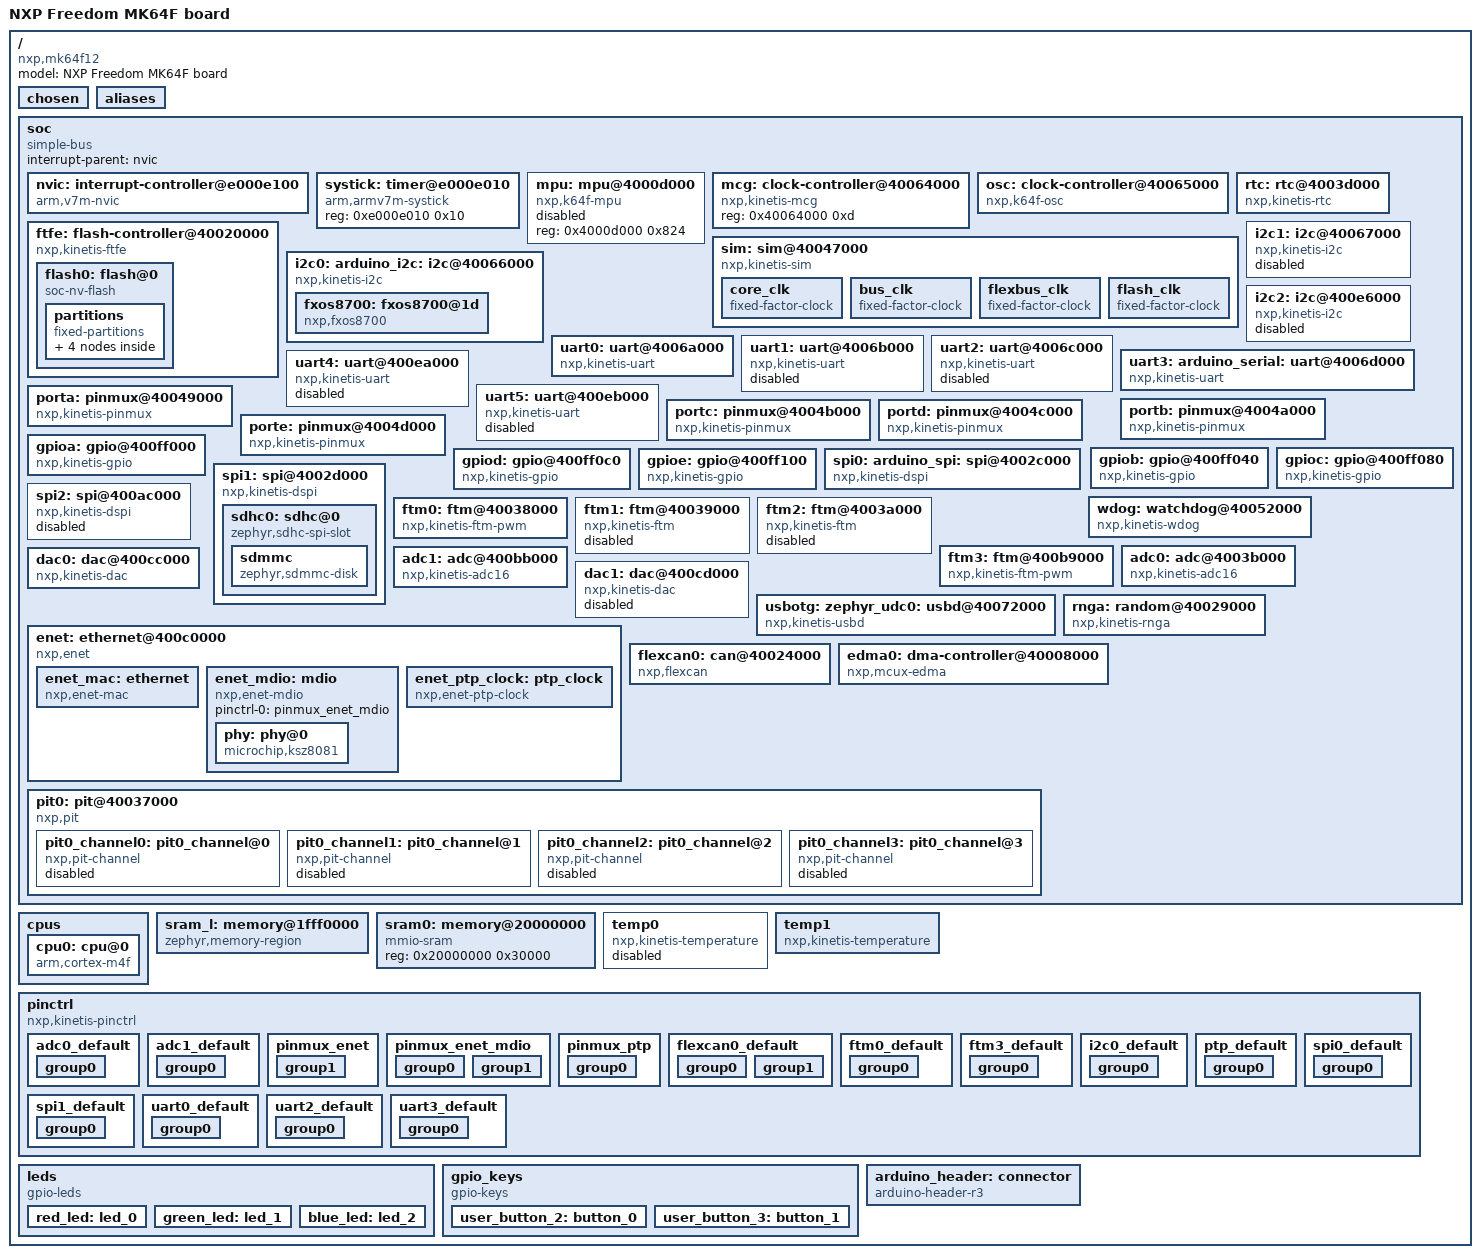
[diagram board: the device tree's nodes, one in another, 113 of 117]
/dts-v1/;

/ {
	#address-cells = < 0x1 >;
	#size-cells = < 0x1 >;
	model = "NXP Freedom MK64F board";
	compatible = "nxp,mk64f12", "nxp,k64f", "nxp,k6x";
	chosen {
		zephyr,entropy = &rnga;
		zephyr,flash-controller = &ftfe;
		zephyr,sram = &sram0;
		zephyr,flash = &flash0;
		zephyr,code-partition = &slot0_partition;
		zephyr,console = &uart0;
		zephyr,shell-uart = &uart0;
		zephyr,uart-pipe = &uart0;
		zephyr,canbus = &flexcan0;
		zephyr,uart-mcumgr = &uart0;
	};
	aliases {
		watchdog0 = &wdog;
		led0 = &green_led;
		led1 = &blue_led;
		led2 = &red_led;
		sw0 = &user_button_3;
		sw1 = &user_button_2;
		magn0 = &fxos8700;
		accel0 = &fxos8700;
	};
	soc {
		#address-cells = < 0x1 >;
		#size-cells = < 0x1 >;
		compatible = "simple-bus";
		interrupt-parent = < &nvic >;
		ranges;
		nvic: interrupt-controller@e000e100 {
			#address-cells = < 0x1 >;
			compatible = "arm,v7m-nvic";
			reg = < 0xe000e100 0xc00 >;
			interrupt-controller;
			#interrupt-cells = < 0x2 >;
			arm,num-irq-priority-bits = < 0x4 >;
			phandle = < 0x1 >;
		};
		systick: timer@e000e010 {
			compatible = "arm,armv7m-systick";
			reg = < 0xe000e010 0x10 >;
		};
		mpu: mpu@4000d000 {
			compatible = "nxp,k64f-mpu";
			reg = < 0x4000d000 0x824 >;
			status = "disabled";
		};
		mcg: clock-controller@40064000 {
			compatible = "nxp,kinetis-mcg";
			reg = < 0x40064000 0xd >;
			#clock-cells = < 0x1 >;
			phandle = < 0x2 >;
		};
		osc: clock-controller@40065000 {
			compatible = "nxp,k64f-osc";
			reg = < 0x40065000 0x4 >;
			enable-external-reference;
		};
		rtc: rtc@4003d000 {
			compatible = "nxp,kinetis-rtc";
			reg = < 0x4003d000 0x1000 >;
			interrupts = < 0x2e 0x0 >, < 0x2f 0x0 >;
			interrupt-names = "alarm", "seconds";
			clock-frequency = < 0x8000 >;
			prescaler = < 0x8000 >;
		};
		sim: sim@40047000 {
			compatible = "nxp,kinetis-sim";
			reg = < 0x40047000 0x1060 >;
			#clock-cells = < 0x3 >;
			pllfll-select = < 0x1 >;
			er32k-select = < 0x2 >;
			phandle = < 0x3 >;
			core_clk {
				compatible = "fixed-factor-clock";
				clocks = < &mcg 0x1 >;
				clock-div = < 0x1 >;
				#clock-cells = < 0x0 >;
			};
			bus_clk {
				compatible = "fixed-factor-clock";
				clocks = < &mcg 0x1 >;
				clock-div = < 0x2 >;
				#clock-cells = < 0x0 >;
			};
			flexbus_clk {
				compatible = "fixed-factor-clock";
				clocks = < &mcg 0x1 >;
				clock-div = < 0x3 >;
				#clock-cells = < 0x0 >;
			};
			flash_clk {
				compatible = "fixed-factor-clock";
				clocks = < &mcg 0x1 >;
				clock-div = < 0x5 >;
				#clock-cells = < 0x0 >;
			};
		};
		ftfe: flash-controller@40020000 {
			compatible = "nxp,kinetis-ftfe";
			reg = < 0x40020000 0x18 >;
			interrupts = < 0x12 0x0 >, < 0x13 0x0 >;
			interrupt-names = "command-complete", "read-collision";
			status = "okay";
			#address-cells = < 0x1 >;
			#size-cells = < 0x1 >;
			flash0: flash@0 {
				compatible = "soc-nv-flash";
				reg = < 0x0 0x100000 >;
				erase-block-size = < 0x1000 >;
				write-block-size = < 0x8 >;
				partitions {
					compatible = "fixed-partitions";
					#address-cells = < 0x1 >;
					#size-cells = < 0x1 >;
					boot_partition: partition@0 {
						label = "mcuboot";
						reg = < 0x0 0x10000 >;
						read-only;
					};
					slot0_partition: partition@10000 {
						label = "image-0";
						reg = < 0x10000 0x6a000 >;
					};
					slot1_partition: partition@7a000 {
						label = "image-1";
						reg = < 0x7a000 0x68000 >;
					};
					storage_partition: partition@e2000 {
						label = "storage";
						reg = < 0xe2000 0x1e000 >;
					};
				};
			};
		};
		i2c0: arduino_i2c: i2c@40066000 {
			compatible = "nxp,kinetis-i2c";
			clock-frequency = < 0x186a0 >;
			#address-cells = < 0x1 >;
			#size-cells = < 0x0 >;
			reg = < 0x40066000 0x1000 >;
			interrupts = < 0x18 0x0 >;
			clocks = < &sim 0x2 0x1034 0x6 >;
			status = "okay";
			pinctrl-0 = < &i2c0_default >;
			pinctrl-names = "default";
			fxos8700: fxos8700@1d {
				compatible = "nxp,fxos8700";
				reg = < 0x1d >;
				int1-gpios = < &gpioc 0x6 0x1 >;
				int2-gpios = < &gpioc 0xd 0x1 >;
			};
		};
		i2c1: i2c@40067000 {
			compatible = "nxp,kinetis-i2c";
			clock-frequency = < 0x186a0 >;
			#address-cells = < 0x1 >;
			#size-cells = < 0x0 >;
			reg = < 0x40067000 0x1000 >;
			interrupts = < 0x19 0x0 >;
			clocks = < &sim 0x2 0x1034 0x7 >;
			status = "disabled";
		};
		i2c2: i2c@400e6000 {
			compatible = "nxp,kinetis-i2c";
			clock-frequency = < 0x186a0 >;
			#address-cells = < 0x1 >;
			#size-cells = < 0x0 >;
			reg = < 0x400e6000 0x1000 >;
			interrupts = < 0x4a 0x0 >;
			clocks = < &sim 0x2 0x1028 0x6 >;
			status = "disabled";
		};
		uart0: uart@4006a000 {
			compatible = "nxp,kinetis-uart";
			reg = < 0x4006a000 0x1000 >;
			interrupts = < 0x1f 0x0 >, < 0x20 0x0 >;
			interrupt-names = "status", "error";
			clocks = < &sim 0x0 0x1034 0xa >;
			status = "okay";
			current-speed = < 0x1c200 >;
			pinctrl-0 = < &uart0_default >;
			pinctrl-names = "default";
		};
		uart1: uart@4006b000 {
			compatible = "nxp,kinetis-uart";
			reg = < 0x4006b000 0x1000 >;
			interrupts = < 0x21 0x0 >, < 0x22 0x0 >;
			interrupt-names = "status", "error";
			clocks = < &sim 0x0 0x1034 0xb >;
			status = "disabled";
		};
		uart2: uart@4006c000 {
			compatible = "nxp,kinetis-uart";
			reg = < 0x4006c000 0x1000 >;
			interrupts = < 0x23 0x0 >, < 0x24 0x0 >;
			interrupt-names = "status", "error";
			clocks = < &sim 0x2 0x1034 0xc >;
			status = "disabled";
			pinctrl-0 = < &uart2_default >;
			pinctrl-names = "default";
		};
		uart3: arduino_serial: uart@4006d000 {
			compatible = "nxp,kinetis-uart";
			reg = < 0x4006d000 0x1000 >;
			interrupts = < 0x25 0x0 >, < 0x26 0x0 >;
			interrupt-names = "status", "error";
			clocks = < &sim 0x2 0x1034 0xd >;
			status = "okay";
			current-speed = < 0x1c200 >;
			pinctrl-0 = < &uart3_default >;
			pinctrl-names = "default";
		};
		uart4: uart@400ea000 {
			compatible = "nxp,kinetis-uart";
			reg = < 0x400ea000 0x1000 >;
			interrupts = < 0x42 0x0 >, < 0x43 0x0 >;
			interrupt-names = "status", "error";
			clocks = < &sim 0x2 0x1028 0xa >;
			status = "disabled";
		};
		uart5: uart@400eb000 {
			compatible = "nxp,kinetis-uart";
			reg = < 0x400eb000 0x1000 >;
			interrupts = < 0x44 0x0 >, < 0x45 0x0 >;
			interrupt-names = "status", "error";
			clocks = < &sim 0x2 0x1028 0xb >;
			status = "disabled";
		};
		porta: pinmux@40049000 {
			compatible = "nxp,kinetis-pinmux";
			reg = < 0x40049000 0xd0 >;
			clocks = < &sim 0x2 0x1038 0x9 >;
			phandle = < 0x9 >;
		};
		portb: pinmux@4004a000 {
			compatible = "nxp,kinetis-pinmux";
			reg = < 0x4004a000 0xd0 >;
			clocks = < &sim 0x2 0x1038 0xa >;
			phandle = < 0xa >;
		};
		portc: pinmux@4004b000 {
			compatible = "nxp,kinetis-pinmux";
			reg = < 0x4004b000 0xd0 >;
			clocks = < &sim 0x2 0x1038 0xb >;
			phandle = < 0xb >;
		};
		portd: pinmux@4004c000 {
			compatible = "nxp,kinetis-pinmux";
			reg = < 0x4004c000 0xd0 >;
			clocks = < &sim 0x2 0x1038 0xc >;
			phandle = < 0xc >;
		};
		porte: pinmux@4004d000 {
			compatible = "nxp,kinetis-pinmux";
			reg = < 0x4004d000 0xd0 >;
			clocks = < &sim 0x2 0x1038 0xd >;
			phandle = < 0xd >;
		};
		gpioa: gpio@400ff000 {
			compatible = "nxp,kinetis-gpio";
			status = "okay";
			reg = < 0x400ff000 0x40 >;
			interrupts = < 0x3b 0x2 >;
			gpio-controller;
			#gpio-cells = < 0x2 >;
			nxp,kinetis-port = < &porta >;
			phandle = < 0x20 >;
		};
		gpiob: gpio@400ff040 {
			compatible = "nxp,kinetis-gpio";
			status = "okay";
			reg = < 0x400ff040 0x40 >;
			interrupts = < 0x3c 0x2 >;
			gpio-controller;
			#gpio-cells = < 0x2 >;
			nxp,kinetis-port = < &portb >;
			phandle = < 0x1f >;
		};
		gpioc: gpio@400ff080 {
			compatible = "nxp,kinetis-gpio";
			status = "okay";
			reg = < 0x400ff080 0x40 >;
			interrupts = < 0x3d 0x2 >;
			gpio-controller;
			#gpio-cells = < 0x2 >;
			nxp,kinetis-port = < &portc >;
			phandle = < 0x5 >;
		};
		gpiod: gpio@400ff0c0 {
			compatible = "nxp,kinetis-gpio";
			status = "okay";
			reg = < 0x400ff0c0 0x40 >;
			interrupts = < 0x3e 0x2 >;
			gpio-controller;
			#gpio-cells = < 0x2 >;
			nxp,kinetis-port = < &portd >;
			phandle = < 0x21 >;
		};
		gpioe: gpio@400ff100 {
			compatible = "nxp,kinetis-gpio";
			status = "okay";
			reg = < 0x400ff100 0x40 >;
			interrupts = < 0x3f 0x2 >;
			gpio-controller;
			#gpio-cells = < 0x2 >;
			nxp,kinetis-port = < &porte >;
			phandle = < 0x11 >;
		};
		spi0: arduino_spi: spi@4002c000 {
			compatible = "nxp,kinetis-dspi";
			reg = < 0x4002c000 0x88 >;
			interrupts = < 0x1a 0x3 >;
			dmas = < &edma0 0x0 0xe >, < &edma0 0x0 0xf >;
			dma-names = "rx", "tx";
			rx-fifo-size = < 0x4 >;
			tx-fifo-size = < 0x4 >;
			clocks = < &sim 0x2 0x103c 0xc >;
			#address-cells = < 0x1 >;
			#size-cells = < 0x0 >;
			status = "okay";
			pinctrl-0 = < &spi0_default >;
			pinctrl-names = "default";
		};
		spi1: spi@4002d000 {
			compatible = "nxp,kinetis-dspi";
			reg = < 0x4002d000 0x88 >;
			interrupts = < 0x1b 0x3 >;
			dmas = < &edma0 0x0 0x10 >, < &edma0 0x0 0x10 >;
			dma-names = "rx", "tx";
			rx-fifo-size = < 0x1 >;
			tx-fifo-size = < 0x1 >;
			nxp,rx-tx-chn-share;
			clocks = < &sim 0x2 0x103c 0xd >;
			#address-cells = < 0x1 >;
			#size-cells = < 0x0 >;
			status = "okay";
			pinctrl-0 = < &spi1_default >;
			pinctrl-names = "default";
			cs-gpios = < &gpioe 0x4 0x1 >;
			sdhc0: sdhc@0 {
				compatible = "zephyr,sdhc-spi-slot";
				reg = < 0x0 >;
				status = "okay";
				spi-max-frequency = < 0x16e3600 >;
				sdmmc {
					compatible = "zephyr,sdmmc-disk";
					status = "okay";
				};
			};
		};
		spi2: spi@400ac000 {
			compatible = "nxp,kinetis-dspi";
			reg = < 0x400ac000 0x88 >;
			interrupts = < 0x41 0x3 >;
			dmas = < &edma0 0x0 0x26 >, < &edma0 0x0 0x27 >;
			dma-names = "rx", "tx";
			rx-fifo-size = < 0x1 >;
			tx-fifo-size = < 0x1 >;
			nxp,rx-tx-chn-share;
			clocks = < &sim 0x2 0x1030 0xc >;
			#address-cells = < 0x1 >;
			#size-cells = < 0x0 >;
			status = "disabled";
		};
		wdog: watchdog@40052000 {
			compatible = "nxp,kinetis-wdog";
			reg = < 0x40052000 0x10 >;
			interrupts = < 0x16 0x0 >;
			clocks = < &sim 0x13 0x0 0x0 >;
		};
		ftm0: ftm@40038000 {
			compatible = "nxp,kinetis-ftm-pwm";
			reg = < 0x40038000 0x98 >;
			interrupts = < 0x2a 0x0 >;
			clocks = < &mcg 0x0 >;
			prescaler = < 0x10 >;
			status = "okay";
			#pwm-cells = < 0x3 >;
			pinctrl-0 = < &ftm0_default >;
			pinctrl-names = "default";
			clock-source = "fixed";
		};
		ftm1: ftm@40039000 {
			compatible = "nxp,kinetis-ftm";
			reg = < 0x40039000 0x98 >;
			interrupts = < 0x2b 0x0 >;
			clocks = < &mcg 0x0 >;
			prescaler = < 0x10 >;
			status = "disabled";
		};
		ftm2: ftm@4003a000 {
			compatible = "nxp,kinetis-ftm";
			reg = < 0x4003a000 0x98 >;
			interrupts = < 0x2c 0x0 >;
			clocks = < &mcg 0x0 >;
			prescaler = < 0x10 >;
			status = "disabled";
		};
		ftm3: ftm@400b9000 {
			compatible = "nxp,kinetis-ftm-pwm";
			reg = < 0x400b9000 0x98 >;
			interrupts = < 0x47 0x0 >;
			clocks = < &mcg 0x0 >;
			prescaler = < 0x10 >;
			status = "okay";
			#pwm-cells = < 0x3 >;
			pinctrl-0 = < &ftm3_default >;
			pinctrl-names = "default";
			clock-source = "fixed";
		};
		adc0: adc@4003b000 {
			compatible = "nxp,kinetis-adc16";
			reg = < 0x4003b000 0x70 >;
			clocks = < &sim 0x7 0x0 0xf >, < &sim 0x7 0x7 0x80 >;
			dmas = < &edma0 0x0 0x28 >;
			dma-names = "adc0";
			clk-source = < 0x0 >;
			interrupts = < 0x27 0x0 >;
			status = "okay";
			#io-channel-cells = < 0x1 >;
			pinctrl-0 = < &adc0_default >;
			pinctrl-names = "default";
			phandle = < 0x1d >;
		};
		adc1: adc@400bb000 {
			compatible = "nxp,kinetis-adc16";
			reg = < 0x400bb000 0x70 >;
			clocks = < &sim 0x7 0x8 0xf00 >, < &sim 0x7 0xf 0x8000 >;
			dmas = < &edma0 0x0 0x29 >;
			dma-names = "adc1";
			clk-source = < 0x0 >;
			interrupts = < 0x49 0x0 >;
			status = "okay";
			#io-channel-cells = < 0x1 >;
			pinctrl-0 = < &adc1_default >;
			pinctrl-names = "default";
			phandle = < 0x1e >;
		};
		dac0: dac@400cc000 {
			compatible = "nxp,kinetis-dac";
			reg = < 0x400cc000 0x1000 >;
			interrupts = < 0x38 0x0 >;
			voltage-reference = < 0x2 >;
			status = "okay";
			#io-channel-cells = < 0x1 >;
		};
		dac1: dac@400cd000 {
			compatible = "nxp,kinetis-dac";
			reg = < 0x400cd000 0x1000 >;
			interrupts = < 0x48 0x0 >;
			voltage-reference = < 0x1 >;
			status = "disabled";
			#io-channel-cells = < 0x1 >;
		};
		usbotg: zephyr_udc0: usbd@40072000 {
			compatible = "nxp,kinetis-usbd";
			reg = < 0x40072000 0x1000 >;
			interrupts = < 0x35 0x1 >;
			interrupt-names = "usb_otg";
			num-bidir-endpoints = < 0x8 >;
			status = "okay";
		};
		enet: ethernet@400c0000 {
			compatible = "nxp,enet";
			reg = < 0x400c0000 0x620 >;
			clocks = < &sim 0x10e1 0x0 0x0 >;
			enet_mac: ethernet {
				compatible = "nxp,enet-mac";
				interrupts = < 0x53 0x0 >, < 0x54 0x0 >, < 0x55 0x0 >;
				interrupt-names = "TX", "RX", "ERR";
				nxp,mdio = < &enet_mdio >;
				nxp,ptp-clock = < &enet_ptp_clock >;
				phy-connection-type = "rmii";
				status = "okay";
				pinctrl-0 = < &pinmux_enet >;
				pinctrl-names = "default";
				phy-handle = < &phy >;
				zephyr,random-mac-address;
			};
			enet_mdio: mdio {
				compatible = "nxp,enet-mdio";
				status = "okay";
				#address-cells = < 0x1 >;
				#size-cells = < 0x0 >;
				pinctrl-0 = < &pinmux_enet_mdio >;
				pinctrl-names = "default";
				phandle = < 0x16 >;
				phy: phy@0 {
					compatible = "microchip,ksz8081";
					reg = < 0x0 >;
					status = "okay";
					microchip,interface-type = "rmii-25MHz";
					phandle = < 0x19 >;
				};
			};
			enet_ptp_clock: ptp_clock {
				compatible = "nxp,enet-ptp-clock";
				interrupts = < 0x52 0x0 >;
				interrupt-names = "IEEE1588_TMR";
				clocks = < &sim 0x10e2 0x0 0x0 >;
				status = "okay";
				pinctrl-0 = < &pinmux_ptp >;
				pinctrl-names = "default";
				phandle = < 0x17 >;
			};
		};
		rnga: random@40029000 {
			compatible = "nxp,kinetis-rnga";
			reg = < 0x40029000 0x1000 >;
			status = "okay";
			interrupts = < 0x17 0x0 >;
		};
		flexcan0: can@40024000 {
			compatible = "nxp,flexcan";
			reg = < 0x40024000 0x1000 >;
			interrupts = < 0x4b 0x0 >, < 0x4c 0x0 >, < 0x4d 0x0 >, < 0x4e 0x0 >, < 0x4f 0x0 >, < 0x50 0x0 >;
			interrupt-names = "mb-0-15", "bus-off", "error", "tx-warning", "rx-warning", "wake-up";
			clocks = < &sim 0x2 0x103c 0x4 >;
			clk-source = < 0x1 >;
			status = "okay";
			pinctrl-0 = < &flexcan0_default >;
			pinctrl-names = "default";
		};
		edma0: dma-controller@40008000 {
			#dma-cells = < 0x2 >;
			compatible = "nxp,mcux-edma";
			dma-channels = < 0x10 >;
			dma-requests = < 0x40 >;
			nxp,mem2mem;
			reg = < 0x40008000 0x1000 >, < 0x40021000 0x1000 >;
			interrupts = < 0x0 0x0 >, < 0x1 0x0 >, < 0x2 0x0 >, < 0x3 0x0 >, < 0x4 0x0 >, < 0x5 0x0 >, < 0x6 0x0 >, < 0x7 0x0 >, < 0x8 0x0 >, < 0x9 0x0 >, < 0xa 0x0 >, < 0xb 0x0 >, < 0xc 0x0 >, < 0xd 0x0 >, < 0xe 0x0 >, < 0xf 0x0 >, < 0x10 0x0 >;
			clocks = < &sim 0x0 0x1040 0x2 >, < &sim 0x2 0x103c 0x2 >;
			status = "okay";
			phandle = < 0xe >;
		};
		pit0: pit@40037000 {
			compatible = "nxp,pit";
			reg = < 0x40037000 0x1000 >;
			clocks = < &sim 0x2 0x103c 0x17 >;
			status = "okay";
			max-load-value = < 0xffffffff >;
			#address-cells = < 0x1 >;
			#size-cells = < 0x0 >;
			pit0_channel0: pit0_channel@0 {
				compatible = "nxp,pit-channel";
				reg = < 0x0 >;
				interrupts = < 0x30 0x0 >;
				status = "disabled";
			};
			pit0_channel1: pit0_channel@1 {
				compatible = "nxp,pit-channel";
				reg = < 0x1 >;
				interrupts = < 0x31 0x0 >;
				status = "disabled";
			};
			pit0_channel2: pit0_channel@2 {
				compatible = "nxp,pit-channel";
				reg = < 0x2 >;
				interrupts = < 0x32 0x0 >;
				status = "disabled";
			};
			pit0_channel3: pit0_channel@3 {
				compatible = "nxp,pit-channel";
				reg = < 0x3 >;
				interrupts = < 0x33 0x0 >;
				status = "disabled";
			};
		};
	};
	cpus {
		#address-cells = < 0x1 >;
		#size-cells = < 0x0 >;
		cpu0: cpu@0 {
			device_type = "cpu";
			compatible = "arm,cortex-m4f";
			reg = < 0x0 >;
			clock-frequency = < 0x7270e00 >;
		};
	};
	sram_l: memory@1fff0000 {
		compatible = "zephyr,memory-region", "mmio-sram";
		reg = < 0x1fff0000 0x10000 >;
		zephyr,memory-region = "SRAML";
	};
	sram0: memory@20000000 {
		compatible = "mmio-sram";
		reg = < 0x20000000 0x30000 >;
	};
	temp0: temp0 {
		compatible = "nxp,kinetis-temperature";
		io-channels = < &adc0 0x1a >, < &adc0 0x1b >;
		io-channel-names = "SENSOR", "BANDGAP";
		bandgap-voltage = < 0xf4240 >;
		vtemp25 = < 0xaece0 >;
		sensor-slope-cold = < 0x654 >;
		sensor-slope-hot = < 0x654 >;
		status = "disabled";
	};
	temp1: temp1 {
		compatible = "nxp,kinetis-temperature";
		io-channels = < &adc1 0x1a >, < &adc1 0x1b >;
		io-channel-names = "SENSOR", "BANDGAP";
		bandgap-voltage = < 0xf4240 >;
		vtemp25 = < 0xaece0 >;
		sensor-slope-cold = < 0x654 >;
		sensor-slope-hot = < 0x654 >;
		status = "okay";
	};
	pinctrl: pinctrl {
		compatible = "nxp,kinetis-pinctrl";
		status = "okay";
		adc0_default: adc0_default {
			phandle = < 0x14 >;
			group0 {
				pinmux = < 0x20000000 >;
				drive-strength = "low";
				slew-rate = "fast";
			};
		};
		adc1_default: adc1_default {
			phandle = < 0x15 >;
			group0 {
				pinmux = < 0x12800000 >;
				drive-strength = "low";
				slew-rate = "fast";
			};
		};
		pinmux_enet: pinmux_enet {
			phandle = < 0x18 >;
			group1 {
				pinmux = < 0x1400400 >, < 0x3000400 >, < 0x3400400 >, < 0x3800400 >, < 0x3c00400 >, < 0x4000400 >, < 0x4400400 >;
				drive-strength = "low";
				slew-rate = "fast";
			};
		};
		pinmux_enet_mdio: pinmux_enet_mdio {
			phandle = < 0x1a >;
			group0 {
				pinmux = < 0x10000400 >;
				drive-strength = "low";
				drive-open-drain;
				bias-pull-up;
				slew-rate = "fast";
			};
			group1 {
				pinmux = < 0x10400400 >;
				drive-strength = "low";
				slew-rate = "fast";
			};
		};
		pinmux_ptp: pinmux_ptp {
			phandle = < 0x1b >;
			group0 {
				pinmux = < 0x24000400 >, < 0x24400400 >, < 0x24800400 >;
				drive-strength = "low";
				slew-rate = "fast";
			};
		};
		flexcan0_default: flexcan0_default {
			phandle = < 0x1c >;
			group0 {
				pinmux = < 0x14c00200 >;
				drive-strength = "low";
				bias-pull-up;
				slew-rate = "fast";
			};
			group1 {
				pinmux = < 0x14800200 >;
				drive-strength = "low";
				slew-rate = "fast";
			};
		};
		ftm0_default: ftm0_default {
			phandle = < 0x12 >;
			group0 {
				pinmux = < 0x20400400 >;
				drive-strength = "low";
				slew-rate = "fast";
			};
		};
		ftm3_default: ftm3_default {
			phandle = < 0x13 >;
			group0 {
				pinmux = < 0x22000300 >, < 0x22400300 >;
				drive-strength = "low";
				slew-rate = "fast";
			};
		};
		i2c0_default: i2c0_default {
			phandle = < 0x4 >;
			group0 {
				pinmux = < 0x46000500 >, < 0x46400500 >;
				drive-strength = "low";
				drive-open-drain;
				slew-rate = "fast";
			};
		};
		ptp_default: ptp_default {
			group0 {
				pinmux = < 0x24000400 >, < 0x24400400 >, < 0x24800400 >;
				drive-strength = "low";
				slew-rate = "fast";
			};
		};
		spi0_default: spi0_default {
			phandle = < 0xf >;
			group0 {
				pinmux = < 0x30000200 >, < 0x30400200 >, < 0x30800200 >, < 0x30c00200 >;
				drive-strength = "low";
				slew-rate = "fast";
			};
		};
		spi1_default: spi1_default {
			phandle = < 0x10 >;
			group0 {
				pinmux = < 0x41000200 >, < 0x40800200 >, < 0x40c00700 >, < 0x40400700 >;
				drive-strength = "low";
				slew-rate = "fast";
			};
		};
		uart0_default: uart0_default {
			phandle = < 0x6 >;
			group0 {
				pinmux = < 0x14000300 >, < 0x14400300 >;
				drive-strength = "low";
				slew-rate = "fast";
			};
		};
		uart2_default: uart2_default {
			phandle = < 0x7 >;
			group0 {
				pinmux = < 0x30400300 >, < 0x30000300 >, < 0x30800300 >, < 0x30c00300 >;
				drive-strength = "low";
				slew-rate = "fast";
			};
		};
		uart3_default: uart3_default {
			phandle = < 0x8 >;
			group0 {
				pinmux = < 0x24000300 >, < 0x24400300 >;
				drive-strength = "low";
				slew-rate = "fast";
			};
		};
	};
	leds {
		compatible = "gpio-leds";
		red_led: led_0 {
			gpios = < &gpiob 0x16 0x1 >;
			label = "User LD1";
		};
		green_led: led_1 {
			gpios = < &gpioe 0x1a 0x1 >;
			label = "User LD2";
		};
		blue_led: led_2 {
			gpios = < &gpiob 0x15 0x1 >;
			label = "User LD3";
		};
	};
	gpio_keys {
		compatible = "gpio-keys";
		user_button_2: button_0 {
			label = "User SW2";
			gpios = < &gpioc 0x6 0x1 >;
			zephyr,code = < 0xb >;
		};
		user_button_3: button_1 {
			label = "User SW3";
			gpios = < &gpioa 0x4 0x1 >;
			zephyr,code = < 0x2 >;
		};
	};
	arduino_header: connector {
		compatible = "arduino-header-r3";
		#gpio-cells = < 0x2 >;
		gpio-map-mask = < 0xffffffff 0xffffffc0 >;
		gpio-map-pass-thru = < 0x0 0x3f >;
		gpio-map = < 0x0 0x0 &gpiob 0x2 0x0 >, < 0x1 0x0 &gpiob 0x3 0x0 >, < 0x2 0x0 &gpiob 0xa 0x0 >, < 0x3 0x0 &gpiob 0xb 0x0 >, < 0x4 0x0 &gpioc 0xb 0x0 >, < 0x5 0x0 &gpioc 0xa 0x0 >, < 0x6 0x0 &gpioc 0x10 0x0 >, < 0x7 0x0 &gpioc 0x11 0x0 >, < 0x8 0x0 &gpiob 0x9 0x0 >, < 0x9 0x0 &gpioa 0x1 0x0 >, < 0xa 0x0 &gpiob 0x17 0x0 >, < 0xb 0x0 &gpioa 0x2 0x0 >, < 0xc 0x0 &gpioc 0x2 0x0 >, < 0xd 0x0 &gpioc 0x3 0x0 >, < 0xe 0x0 &gpioc 0xc 0x0 >, < 0xf 0x0 &gpioc 0x4 0x0 >, < 0x10 0x0 &gpiod 0x0 0x0 >, < 0x11 0x0 &gpiod 0x2 0x0 >, < 0x12 0x0 &gpiod 0x3 0x0 >, < 0x13 0x0 &gpiod 0x1 0x0 >, < 0x14 0x0 &gpioe 0x19 0x0 >, < 0x15 0x0 &gpioe 0x18 0x0 >;
	};
};
